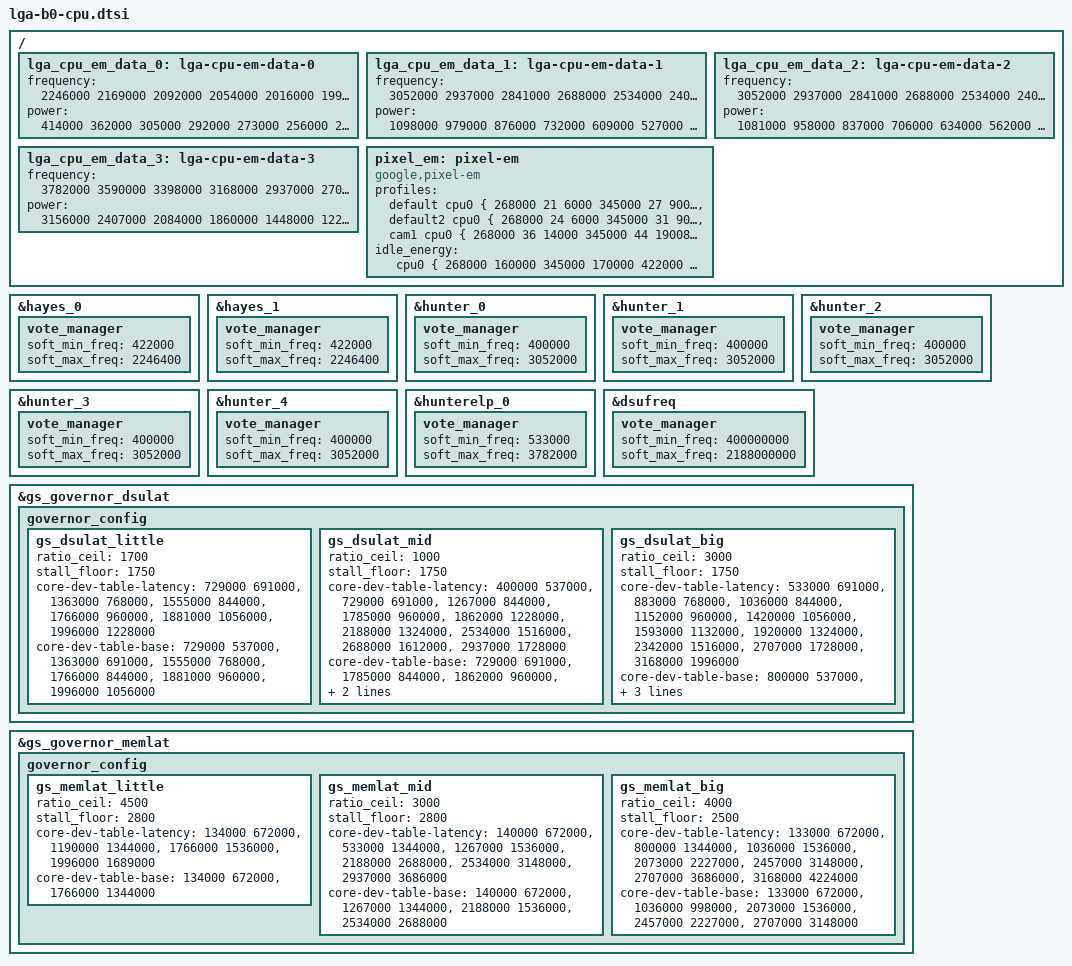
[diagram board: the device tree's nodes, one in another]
// SPDX-License-Identifier: GPL-2.0 OR BSD-3-Clause

&hayes_0 {
	vote_manager {
		soft_min_freq =  <422000>;
		soft_max_freq = <2246400>;
	};
};

&hayes_1 {
	vote_manager {
		soft_min_freq =  <422000>;
		soft_max_freq = <2246400>;
	};
};

&hunter_0 {
	vote_manager {
		soft_min_freq =  <400000>;
		soft_max_freq = <3052000>;
	};
};

&hunter_1 {
	vote_manager {
		soft_min_freq =  <400000>;
		soft_max_freq = <3052000>;
	};
};

&hunter_2 {
	vote_manager {
		soft_min_freq =  <400000>;
		soft_max_freq = <3052000>;
	};
};

&hunter_3 {
	vote_manager {
		soft_min_freq =  <400000>;
		soft_max_freq = <3052000>;
	};
};

&hunter_4 {
	vote_manager {
		soft_min_freq =  <400000>;
		soft_max_freq = <3052000>;
	};
};

&hunterelp_0 {
	vote_manager {
		soft_min_freq =  <533000>;
		soft_max_freq = <3782000>;
	};
};

&dsufreq {
	vote_manager {
		soft_min_freq = <400000000>;
		soft_max_freq = <2188000000>;
	};
};

&gs_governor_dsulat {
		governor_config {
			gs_dsulat_little {
				ratio_ceil = <1700>;
				stall_floor = <1750>;
				core-dev-table-latency =
				/* Little CPU    DSU */
				<  729000	 691000 >,
				< 1363000	 768000 >,
				< 1555000	 844000 >,
				< 1766000	 960000 >,
				< 1881000	1056000 >,
				< 1996000	1228000 >;

				core-dev-table-base =
				/* Little CPU    DSU */
				<  729000	 537000 >,
				< 1363000	 691000 >,
				< 1555000	 768000 >,
				< 1766000	 844000 >,
				< 1881000	 960000 >,
				< 1996000	1056000 >;
			};
			gs_dsulat_mid {
				ratio_ceil = <1000>;
				stall_floor = <1750>;
				core-dev-table-latency =
				/* Mid CPU       DSU */
				<  400000	 537000 >,
				<  729000	 691000 >,
				< 1267000	 844000 >,
				< 1785000	 960000 >,
				< 1862000	1228000 >,
				< 2188000	1324000 >,
				< 2534000	1516000 >,
				< 2688000	1612000 >,
				< 2937000	1728000 >;

				core-dev-table-base =
				/* Mid CPU       DSU */
				<  729000	 691000 >,
				< 1785000	 844000 >,
				< 1862000	 960000 >,
				< 2188000	1056000 >,
				< 2688000	1132000 >,
				< 2937000	1516000 >;
			};
			gs_dsulat_big {
				ratio_ceil = <3000>;
				stall_floor = <1750>;
				core-dev-table-latency =
				/* Big CPU       DSU */
				<  533000	 691000 >,
				<  883000	 768000 >,
				< 1036000	 844000 >,
				< 1152000	 960000 >,
				< 1420000	1056000 >,
				< 1593000	1132000 >,
				< 1920000	1324000 >,
				< 2342000	1516000 >,
				< 2707000	1728000 >,
				< 3168000	1996000 >;

				core-dev-table-base =
				/* Big CPU       DSU */
				<  800000	 537000 >,
				<  883000	 691000 >,
				< 1420000	 844000 >,
				< 1593000	 960000 >,
				< 1920000	1056000 >,
				< 2707000	1324000 >,
				< 3168000	1516000 >;
			};
		};
	};

&gs_governor_memlat {
		governor_config {
			gs_memlat_little {
				/* Todo (b/350517173): Update parameters and freq tables. */
				ratio_ceil = <4500>;
				stall_floor = <2800>;
				core-dev-table-latency =
				/* LITTLE CPU	 GMC */
				<  134000	 672000 >,
				< 1190000	1344000 >,
				< 1766000	1536000 >,
				< 1996000	1689000 >;

				core-dev-table-base =
				/* LITTLE CPU    GMC */
				<  134000	 672000 >,
				< 1766000       1344000 >;
			};
			gs_memlat_mid {
				/* Todo (b/350517173): Update parameters and freq tables. */
				ratio_ceil = <3000>;
				stall_floor = <2800>;
				core-dev-table-latency =
				/* MID CPU	 GMC */
				<  140000	 672000 >,
				<  533000	1344000 >,
				< 1267000	1536000 >,
				< 2188000	2688000 >,
				< 2534000	3148000 >,
				< 2937000	3686000 >;

				core-dev-table-base =
				/* MID CPU    	 GMC */
				<  140000	 672000 >,
				< 1267000	1344000 >,
				< 2188000	1536000 >,
				< 2534000	2688000 >;
			};
			gs_memlat_big {
				/* Todo (b/350517173): Update parameters and freq tables. */
				ratio_ceil = <4000>;
				stall_floor = <2500>;
				core-dev-table-latency =
				/* BIG CPU    	 GMC */
				<  133000	 672000 >,
				<  800000	1344000 >,
				< 1036000	1536000 >,
				< 2073000	2227000 >,
				< 2457000	3148000 >,
				< 2707000	3686000 >,
				< 3168000	4224000 >;

				core-dev-table-base =
				/* BIG CPU    	GMC */
				<  133000	 672000 >,
				< 1036000	 998000 >,
				< 2073000       1536000 >,
				< 2457000	2227000 >,
				< 2707000	3148000 >;
			};
		};
	};

/ {
	// the frequency/power list must in decreasing order
	lga_cpu_em_data_0: lga-cpu-em-data-0 {
		frequency = /bits/ 64 <2246000 2169000 2092000 2054000 2016000
					1996000 1881000 1766000 1632000 1555000 1459000 1363000
					1286000 1190000 1036000 883000 729000 533000 460000
					422000 345000 268000>;
		power = /bits/ 64 <414000 362000 305000 292000 273000 256000
					221000 200000 173000 170000 150000 130000 123000 111000
					101000 92000 82000 69000 62000 60000 58000 54000>;
	};

	lga_cpu_em_data_1: lga-cpu-em-data-1 {
		frequency = /bits/ 64 <3052000 2937000 2841000 2688000 2534000 2400000 2284000
					2188000 2092000 1939000 1862000 1785000 1670000 1536000
					1401000 1267000 1075000 921000 729000 652000 533000
					400000 266000 177000>;
		power = /bits/ 64 <1098000 979000 876000 732000 609000 527000 488000 442000
					404000 342000 320000 286000 259000 229000 200000 177000
					149000 130000 111000 102000 64000 48000 39000 30000>;
	};

	lga_cpu_em_data_2: lga-cpu-em-data-2 {
		frequency = /bits/ 64 <3052000 2937000 2841000 2688000 2534000 2400000 2284000
					2188000 2092000 1939000 1862000 1785000 1670000 1536000
					1401000 1267000 1075000 921000 729000 652000 533000
					400000 266000 177000>;
		power = /bits/ 64 <1081000 958000 837000 706000 634000 562000 502000 451000
					402000 347000 313000 287000 261000 239000 206000 182000
					148000 138000 115000 112000 69000 54000 41000 35000>;
	};

	lga_cpu_em_data_3: lga-cpu-em-data-3 {
		frequency =  /bits/ 64 <3782000 3590000 3398000 3168000 2937000 2707000
					2592000 2457000 2342000 2208000 2073000 1920000 1766000
					1593000 1420000 1305000 1152000 1036000 883000 800000
					533000 400000 266000>;
		power = /bits/ 64 <3156000 2407000 2084000 1860000 1448000 1224000
					1095000 947000 855000 804000 706000 621000 561000 495000
					415000 365000 311000 277000 238000 206000 143000 117000
					90000>;
	};

	pixel_em: pixel-em {
		compatible = "google,pixel-em";
		profiles =
			"default
				cpu0 {
				268000 21 6000
				345000 27 9000
				422000 34 12000
				460000 37 14000
				533000 42 18000
				729000 58 43000
				883000 71 51000
				1036000 83 59000
				1190000 95 67000
				1286000 103 75000
				1363000 109 80000
				1459000 116 89000
				1555000 124 97000
				1632000 130 104000
				1766000 141 120000
				1881000 150 135000
				1996000 159 151000
				2016000 161 157000
				2054000 164 169000
				2092000 167 177000
				2169000 173 209000
				2246000 179 242000
				}
				cpu2 {
				177000 41 21000
				266000 62 29000
				400000 93 41000
				533000 124 54000
				652000 151 70000
				729000 170 82000
				921000 214 110000
				1075000 250 134000
				1267000 295 166000
				1401000 326 194000
				1536000 358 221000
				1670000 389 247000
				1785000 416 265000
				1862000 434 296000
				1939000 452 321000
				2092000 487 380000
				2188000 508 420000
				2284000 532 460000
				2400000 559 510000
				2534000 587 582000
				2688000 626 675000
				2841000 656 828000
				2937000 684 929000
				3052000 711 1068000
				}
				cpu5 {
				voltage_table=y
				voltage_scaling_target=7
				frequency_scaling_table=y
				frequency_scaling_target=7
				constraint_type=min
				177000 41 45000 532 266000
				266000 62 53000 532 400000
				400000 93 65000 532 533000
				533000 124 80000 546 800000
				652000 151 94000 561 883000
				729000 170 104000 566 883000
				921000 214 132000 590 883000
				1075000 250 154000 605 883000
				1267000 295 188000 625 883000
				1401000 326 213000 639 883000
				1536000 358 239000 654 883000
				1670000 389 265000 664 883000
				1785000 416 289000 674 883000
				1862000 434 321000 693 883000
				1939000 452 343000 708 883000
				2092000 487 397000 737 883000
				2188000 508 431000 762 883000
				2284000 532 465000 787 883000
				2400000 559 515000 812 883000
				2534000 587 587000 837 883000
				2688000 626 691000 857 883000
				2841000 656 813000 902 883000
				2937000 684 908000 937 883000
				3052000 712 1050000 972 883000
				}
				cpu7 {
				voltage_table=y
				voltage_scaling_target=5
				frequency_scaling_table=y
				frequency_scaling_target=5
				constraint_type=min
				266000 71 85000 532 177000
				400000 114 113000 532 266000
				533000 132 133000 532 400000
				800000 204 192000 546 533000
				883000 244 226000 561 652000
				1036000 267 267000 576 729000
				1152000 300 299000 590 921000
				1305000 350 363000 605 921000
				1420000 376 406000 625 921000
				1593000 415 474000 639 921000
				1766000 436 530000 654 921000
				1920000 494 613000 669 921000
				2073000 537 691000 684 921000
				2208000 590 782000 703 921000
				2342000 620 843000 723 921000
				2457000 645 955000 743 921000
				2592000 726 1117000 762 921000
				2707000 757 1166000 787 921000
				2937000 818 1409000 822 921000
				3168000 824 1831000 877 921000
				3398000 884 2226000 932 921000
				3590000 1011 2861000 987 921000
				3782000 1024 3589000 1061 921000
				}
			",
			"default2
				cpu0 {
				268000 24 6000
				345000 31 9000
				422000 39 12000
				460000 43 14000
				533000 49 18000
				729000 67 43000
				883000 82 51000
				1036000 96 59000
				1190000 110 67000
				1286000 119 75000
				1363000 126 80000
				1459000 134 89000
				1555000 144 97000
				1632000 151 104000
				1766000 163 120000
				1881000 174 135000
				1996000 184 151000
				2016000 186 157000
				2054000 190 169000
				2092000 193 177000
				2169000 200 209000
				2246000 207 242000
				}
				cpu2 {
				177000 47 21000
				266000 72 29000
				400000 108 41000
				533000 144 54000
				652000 175 70000
				729000 197 82000
				921000 248 110000
				1075000 290 134000
				1267000 342 166000
				1401000 378 194000
				1536000 415 221000
				1670000 451 247000
				1785000 482 265000
				1862000 503 296000
				1939000 524 321000
				2092000 564 380000
				2188000 588 420000
				2284000 616 460000
				2400000 648 510000
				2534000 680 582000
				2688000 725 675000
				2841000 760 828000
				2937000 792 929000
				3052000 824 1068000
				}
				cpu5 {
				voltage_table=y
				voltage_scaling_target=7
				frequency_scaling_table=y
				frequency_scaling_target=7
				constraint_type=min
				177000 47 45000 532 266000
				266000 72 53000 532 400000
				400000 108 65000 532 533000
				533000 144 80000 546 800000
				652000 175 94000 561 883000
				729000 197 104000 566 883000
				921000 248 132000 590 883000
				1075000 290 154000 605 883000
				1267000 342 188000 625 883000
				1401000 378 213000 639 883000
				1536000 415 239000 654 883000
				1670000 451 265000 664 883000
				1785000 482 289000 674 883000
				1862000 503 321000 693 883000
				1939000 524 343000 708 883000
				2092000 564 397000 737 883000
				2188000 588 431000 762 883000
				2284000 616 465000 787 883000
				2400000 648 515000 812 883000
				2534000 680 587000 837 883000
				2688000 725 691000 857 883000
				2841000 760 813000 902 883000
				2937000 792 908000 937 883000
				3052000 825 1050000 972 883000 // needs to be greated than cpu2
				}
				cpu7 {
				voltage_table=y
				voltage_scaling_target=5
				frequency_scaling_table=y
				frequency_scaling_target=5
				constraint_type=min
				266000 82 85000 532 177000
				400000 132 113000 532 266000
				533000 153 133000 532 400000
				800000 236 192000 546 533000
				883000 283 226000 561 652000
				1036000 309 267000 576 729000
				1152000 348 299000 590 921000
				1305000 405 363000 605 921000
				1420000 436 406000 625 921000
				1593000 481 474000 639 921000
				1766000 505 530000 654 921000
				1920000 572 613000 669 921000
				2073000 622 691000 684 921000
				2208000 683 782000 703 921000
				2342000 718 843000 723 921000
				2457000 747 955000 743 921000
				2592000 841 1117000 762 921000
				2707000 877 1166000 787 921000
				2937000 948 1409000 822 921000
				3168000 954 1831000 877 921000
				3398000 1021 2226000 932 921000
				3590000 1022 2861000 987 921000
				3782000 1023 3589000 1061 921000
				}
			",
			"cam1
				cpu0 {
				268000 36 14000
				345000 44 19008
				422000 52 24016
				460000 55 26487
				533000 63 31235
				729000 83 43983
				883000 100 54000
				1036000 131 395471
				1190000 162 739175
				1286000 182 953432
				1363000 198 1125283
				1459000 217 1339540
				1555000 237 1553797
				1632000 253 1725649
				1766000 280 2024716
				1881000 304 2281377
				1996000 327 2538039
				2016000 331 2582676
				2054000 339 2667486
				2092000 347 2752296
				2169000 363 2924148
				2246000 379 3096000
				}
				cpu2 {
				177000 31 23000
				266000 56 28451
				400000 95 36658
				533000 133 44804
				652000 167 52092
				729000 190 56808
				921000 245 68567
				1075000 290 78000
				1267000 319 92000
				1401000 351 124877
				1536000 384 158000
				1670000 435 257061
				1785000 480 342076
				1862000 510 399000
				1939000 539 455923
				2092000 598 569030
				2188000 636 640000
				2284000 673 818111
				2400000 719 1033328
				2534000 771 1281942
				2688000 832 1567662
				2841000 892 1851526
				2937000 929 2029637
				3052000 975 2243000
				}
				cpu5 {
				177000 31 23000
				266000 56 28451
				400000 95 36658
				533000 133 44804
				652000 167 52092
				729000 190 56808
				921000 245 68567
				1075000 290 78000
				1267000 319 92000
				1401000 351 124877
				1536000 384 158000
				1670000 435 257061
				1785000 480 342076
				1862000 510 399000
				1939000 539 455923
				2092000 598 569030
				2188000 636 640000
				2284000 673 818111
				2400000 719 1033328
				2534000 771 1281942
				2688000 832 1567662
				2841000 892 1851526
				2937000 929 2029637
				3052000 975 2243000
				}
				cpu7 {
				266000 99 101999
				400000 131 127581
				533000 162 152972
				800000 224 203945
				883000 244 219790
				1036000 280 249000
				1152000 325 321549
				1305000 385 417239
				1420000 430 489163
				1593000 497 597362
				1766000 565 705561
				1920000 625 801877
				2073000 685 897567
				2208000 738 982000
				2342000 755 1157177
				2457000 769 1307515
				2592000 786 1484000
				2707000 801 1634338
				2937000 830 1935015
				3168000 860 2237000
				3398000 921 2849833
				3590000 972 3361416
				3782000 1024 3873000
				}
			";
			idle_energy =
			"
				cpu0 {
				268000 160000
				345000 170000
				422000 180000
				460000 370000
				533000 200000
				729000 360000
				883000 390000
				1036000 450000
				1190000 550000
				1286000 640000
				1363000 660000
				1459000 870000
				1555000 900000
				1632000 1020000
				1766000 1400000
				1881000 1340000
				1996000 1810000
				2016000 1770000
				2054000 2080000
				2092000 2300000
				2169000 3450000
				2246000 4140000
				}
				cpu 2 {
				177000 400000
				266000 400000
				400000 400000
				533000 400000
				652000 500000
				729000 400000
				921000 500000
				1075000 600000
				1267000 700000
				1401000 800000
				1536000 800000
				1670000 1000000
				1785000 1200000
				1862000 1000000
				1939000 1300000
				2092000 1200000
				2188000 1700000
				2284000 1600000
				2400000 1600000
				2534000 2200000
				2688000 2200000
				2841000 2700000
				2937000 3100000
				3052000 3100000 /* Todo b/386437172 */
				}
				cpu 5 {
				177000 800000
				266000 700000
				400000 800000
				533000 700000
				652000 900000
				729000 800000
				921000 900000
				1075000 1100000
				1267000 1000000
				1401000 1100000
				1536000 1100000
				1670000 1100000
				1785000 1400000
				1862000 1200000
				1939000 1400000
				2092000 1600000
				2188000 1900000
				2284000 2200000
				2400000 2500000
				2534000 3000000
				2688000 2900000
				2841000 3900000
				2937000 4000000
				3052000 4000000 /* Todo b/386437172 */
				}
				cpu7 {
				266000 2700000
				400000 2900000
				533000 2700000
				800000 3400000
				883000 3200000
				1036000 3600000
				1152000 3500000
				1305000 4300000
				1420000 4500000
				1593000 4700000
				1766000 5600000
				1920000 6500000
				2073000 7200000
				2208000 7000000
				2342000 8700000
				2457000 8600000
				2592000 10600000
				2707000 12000000
				2937000 11500000
				3168000 16100000
				3398000 20400000 /* Todo b/386437172 */
				3590000 20400000
				3782000 20400000
				}
			";
	};

};
